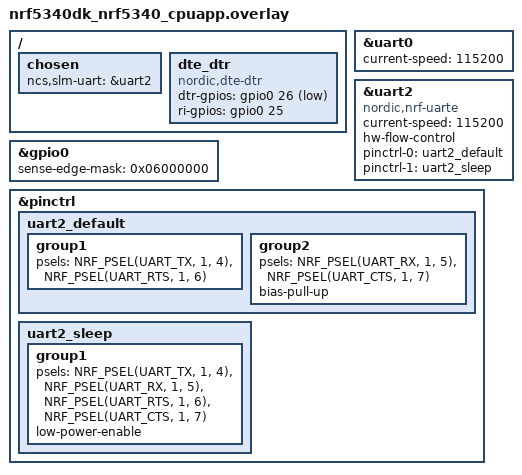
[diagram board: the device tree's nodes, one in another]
/*
 * Copyright (c) 2023 Nordic Semiconductor ASA
 *
 * SPDX-License-Identifier: LicenseRef-Nordic-5-Clause
 */

/ {
	chosen {
		ncs,slm-uart = &uart2;
	};
};

/* Shell UART */
&uart0 {
	current-speed = <115200>;
	status = "okay";
};

/* SLM Shell <-> SLM UART */
&uart2 {
	compatible = "nordic,nrf-uarte";
	current-speed = <115200>;
	status = "okay";
	hw-flow-control;
	pinctrl-0 = <&uart2_default>;
	pinctrl-1 = <&uart2_sleep>;
	pinctrl-names = "default", "sleep";
};

/ {
	dte_dtr: dte_dtr {
		compatible = "nordic,dte-dtr";
		dtr-gpios = <&gpio0 26 GPIO_ACTIVE_LOW>;
		ri-gpios = <&gpio0 25 (GPIO_ACTIVE_HIGH | GPIO_PULL_DOWN)>;
	};
};

&gpio0 {
	status = "okay";
	/* Use PORT event for DTR and RI pins to ensure lower power consumption. */
	sense-edge-mask = <0x06000000>;
};


&pinctrl {
	uart2_default: uart2_default {
		group1 {
			psels = <NRF_PSEL(UART_TX, 1, 4)>,
				<NRF_PSEL(UART_RTS, 1, 6)>;
		};
		group2 {
			psels = <NRF_PSEL(UART_RX, 1, 5)>,
				<NRF_PSEL(UART_CTS, 1, 7)>;
			bias-pull-up;
		};
	};

	uart2_sleep: uart2_sleep {
		group1 {
			psels = <NRF_PSEL(UART_TX, 1, 4)>,
				<NRF_PSEL(UART_RX, 1, 5)>,
				<NRF_PSEL(UART_RTS, 1, 6)>,
				<NRF_PSEL(UART_CTS, 1, 7)>;
			low-power-enable;
		};
	};
};
